VERSION ""

NS_ :

BS_:

BU_: XXX

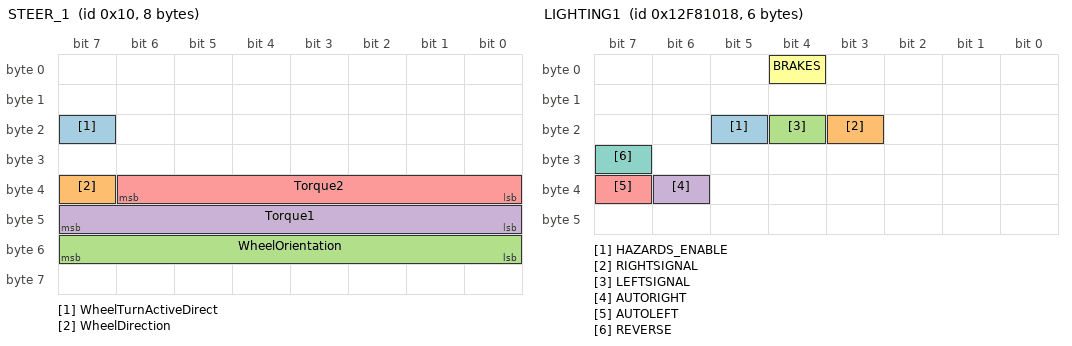
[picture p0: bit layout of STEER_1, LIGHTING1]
BO_ 16 STEER_1: 8 XXX
 SG_ WheelTurnActiveDirect : 23|1@0+ (1,0) [0|255] "" XXX
 SG_ WheelDirection : 39|1@0+ (1,0) [0|1] "" XXX
 SG_ WheelOrientation : 55|8@0+ (1,0) [0|255] "" XXX
 SG_ Torque1 : 40|8@1+ (1,0) [0|255] "" XXX
 SG_ Torque2 : 38|7@0+ (1,0) [0|127] "" XXX

BO_ 516 GAS: 8 XXX
 SG_ UserGasPosition : 1|18@0+ (1,0) [0|65535] "" XXX

BO_ 125 BRAKE1: 8 XXX
 SG_ PedalPosition : 7|16@0+ (1,0) [0|65535] "" XXX

BO_ 318246936 LIGHTING1: 6 XXX
 SG_ HAZARDS_ENABLE : 21|1@0+ (1,0) [0|1] "" XXX
 SG_ RIGHTSIGNAL : 19|1@0+ (1,0) [0|1] "" XXX
 SG_ LEFTSIGNAL : 20|1@0+ (1,0) [0|3] "" XXX
 SG_ AUTORIGHT : 38|1@0+ (1,0) [0|1] "" XXX
 SG_ AUTOLEFT : 39|1@0+ (1,0) [0|1] "" XXX
 SG_ BRAKES : 4|1@0+ (1,0) [0|1] "" XXX
 SG_ REVERSE : 31|1@0+ (1,0) [0|1] "" XXX

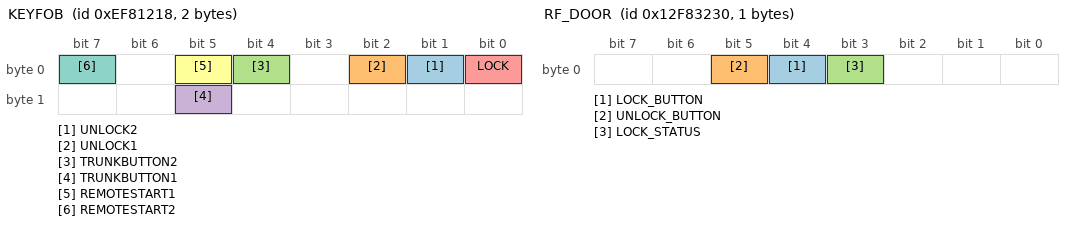
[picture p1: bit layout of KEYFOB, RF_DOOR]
BO_ 251138584 KEYFOB: 2 XXX
 SG_ UNLOCK2 : 1|1@0+ (1,0) [0|1] "" XXX
 SG_ UNLOCK1 : 2|1@0+ (1,0) [0|1] "" XXX
 SG_ TRUNKBUTTON2 : 4|1@0+ (1,0) [0|1] "" XXX
 SG_ TRUNKBUTTON1 : 13|1@0+ (1,0) [0|1] "" XXX
 SG_ LOCK : 0|1@0+ (1,0) [0|1] "" XXX
 SG_ REMOTESTART1 : 5|1@0+ (1,0) [0|1] "" XXX
 SG_ REMOTESTART2 : 7|1@0+ (1,0) [0|1] "" XXX

BO_ 318255664 RF_DOOR: 1 XXX
 SG_ LOCK_BUTTON : 4|1@0+ (1,0) [0|1] "" XXX
 SG_ UNLOCK_BUTTON : 5|1@0+ (1,0) [0|1] "" XXX
 SG_ LOCK_STATUS : 3|1@0+ (1,0) [0|1] "" XXX

BO_ 318255408 DOOR_STATUS2: 8 XXX

BO_ 184057368 LIGHTING2: 3 XXX

BO_ 318264400 LIGHTING3: 8 XXX
 SG_ PARKING_LIGHTS : 6|1@0+ (1,0) [0|1] "" XXX

BO_ 184029464 LIGHTING4: 6 XXX

BO_ 184053784 LIGHTING_STALK1: 3 XXX

BO_ 318259736 RR_DOOR: 1 XXX
 SG_ LOCK_STATUS : 7|1@0+ (1,0) [0|1] "" XXX

BO_ 318288034 HEATED_SEATS: 2 XXX
 SG_ PASS_SEAT : 2|2@0+ (1,0) [0|3] "" XXX
 SG_ DRIVER_SEAT : 6|2@0+ (1,0) [0|3] "" XXX

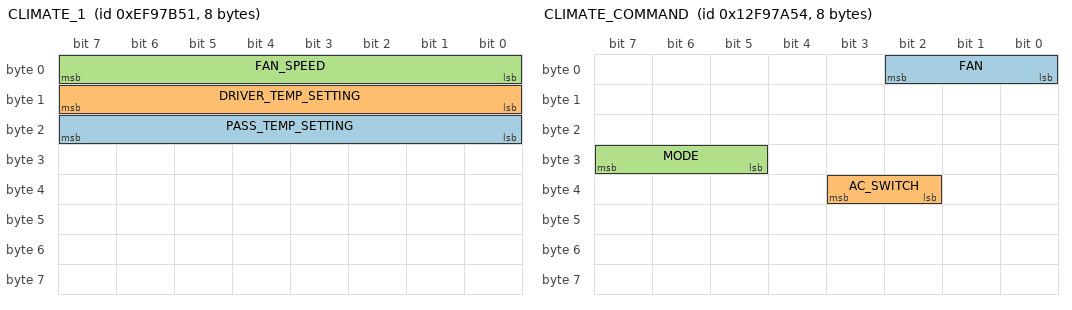
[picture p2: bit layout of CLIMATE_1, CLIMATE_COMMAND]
BO_ 251231057 CLIMATE_1: 8 XXX
 SG_ PASS_TEMP_SETTING : 16|8@1+ (1,0) [0|255] "" XXX
 SG_ DRIVER_TEMP_SETTING : 8|8@1+ (1,0) [0|255] "" XXX
 SG_ FAN_SPEED : 0|8@1+ (1,0) [0|255] "" XXX

BO_ 251142168 DOOR_LOCKS: 1 XXX
 SG_ LOCKACTION_STATUS : 7|2@0+ (1,0) [0|1] "" XXX

BO_ 318339668 CLIMATE_COMMAND: 8 XXX
 SG_ FAN : 0|3@1+ (1,0) [0|7] "" XXX
 SG_ AC_SWITCH : 34|2@1+ (1,0) [0|3] "" XXX
 SG_ MODE : 31|3@0+ (1,0) [0|7] "" XXX

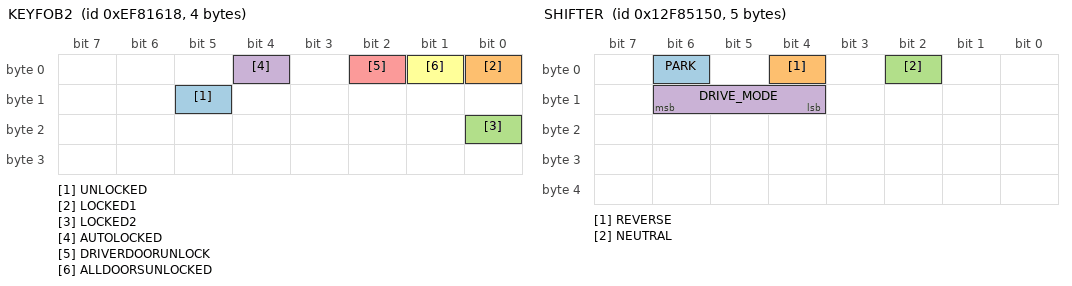
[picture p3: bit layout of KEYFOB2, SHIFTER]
BO_ 251139608 KEYFOB2: 4 XXX
 SG_ UNLOCKED : 13|1@0+ (1,0) [0|1] "" XXX
 SG_ LOCKED1 : 0|1@0+ (1,0) [0|1] "" XXX
 SG_ LOCKED2 : 16|1@0+ (1,0) [0|1] "" XXX
 SG_ AUTOLOCKED : 4|1@0+ (1,0) [0|1] "" XXX
 SG_ DRIVERDOORUNLOCK : 2|1@0+ (1,0) [0|1] "" XXX
 SG_ ALLDOORSUNLOCKED : 1|1@0+ (1,0) [0|1] "" XXX

BO_ 318260272 FRONT_WINDOWS: 2 XXX
 SG_ RF_WINDOWSTATE : 14|1@0+ (1,0) [0|1] "" XXX
 SG_ LF_WINDOWSTATE : 15|1@0+ (1,0) [0|1] "" XXX

BO_ 318263376 CONSOLE_SWITCHES: 6 XXX
 SG_ ECO_SWITCH : 29|1@0+ (1,0) [0|1] "" XXX
 SG_ ENGINE_RPM : 15|16@0+ (1,0) [0|65535] "" XXX

BO_ 318263632 SHIFTER: 5 XXX
 SG_ PARK : 6|1@0+ (1,0) [0|1] "" XXX
 SG_ REVERSE : 4|1@0+ (1,0) [0|1] "" XXX
 SG_ NEUTRAL : 2|1@0+ (1,0) [0|1] "" XXX
 SG_ DRIVE_MODE : 14|3@0+ (1,0) [0|7] "" XXX

BO_ 318337360 STEERING: 3 XXX

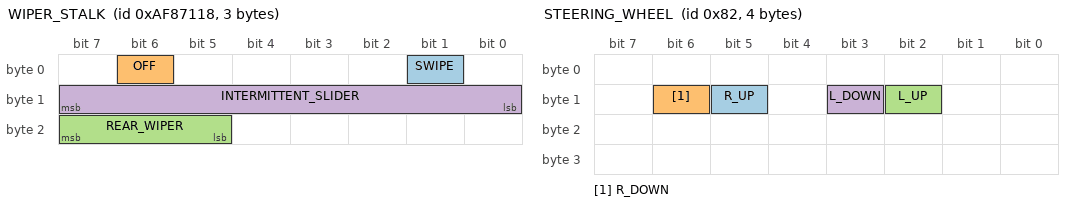
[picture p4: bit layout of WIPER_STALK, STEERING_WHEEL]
BO_ 184054040 WIPER_STALK: 3 XXX
 SG_ SWIPE : 1|1@0+ (1,0) [0|1] "" XXX
 SG_ OFF : 6|1@0+ (1,0) [0|1] "" XXX
 SG_ REAR_WIPER : 23|3@0+ (1,0) [0|7] "" XXX
 SG_ INTERMITTENT_SLIDER : 15|8@0+ (1,0) [0|255] "" XXX

BO_ 130 STEERING_WHEEL: 4 XXX
 SG_ R_UP : 13|1@0+ (1,0) [0|1] "" XXX
 SG_ R_DOWN : 14|1@0+ (1,0) [0|1] "" XXX
 SG_ L_UP : 10|1@0+ (1,0) [0|1] "" XXX
 SG_ L_DOWN : 11|1@0+ (1,0) [0|1] "" XXX

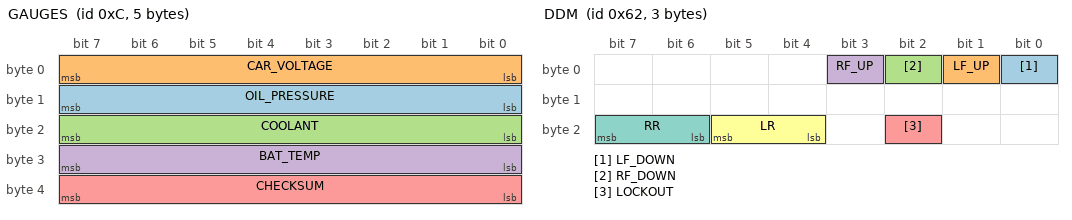
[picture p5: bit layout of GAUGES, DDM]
BO_ 12 GAUGES: 5 XXX
 SG_ OIL_PRESSURE : 15|8@0+ (0.5,0) [0|255] "psi" XXX
 SG_ CAR_VOLTAGE : 7|8@0+ (0.125,0) [0|255] "volts" XXX
 SG_ COOLANT : 23|8@0+ (1,-64) [0|255] "c" XXX
 SG_ BAT_TEMP : 24|8@1+ (1,-64) [0|255] "" XXX
 SG_ CHECKSUM : 39|8@0+ (1,0) [0|255] "" XXX

BO_ 98 DDM: 3 XXX
 SG_ LF_DOWN : 0|1@0+ (1,0) [0|1] "" XXX
 SG_ LF_UP : 1|1@1+ (1,0) [0|1] "" XXX
 SG_ RF_DOWN : 2|1@0+ (1,0) [0|1] "" XXX
 SG_ RF_UP : 3|1@0+ (1,0) [0|1] "" XXX
 SG_ LOCKOUT : 18|1@0+ (1,0) [0|1] "" XXX
 SG_ LR : 21|2@0+ (1,0) [0|1] "" XXX
 SG_ RR : 23|2@0+ (1,0) [0|3] "1 = IDLE, 0 = DOWN, 3 = UP" XXX

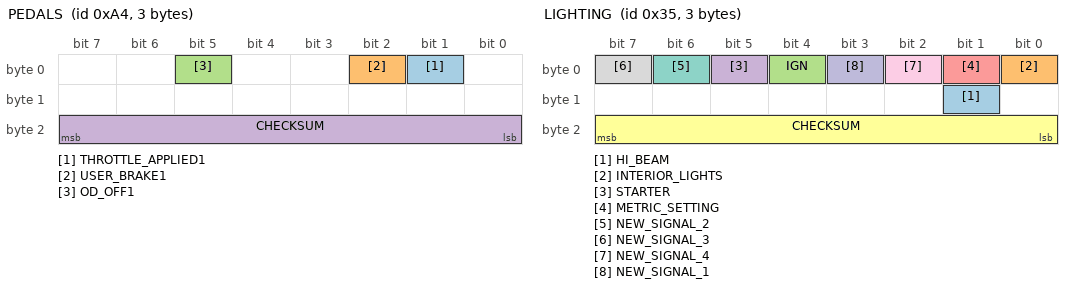
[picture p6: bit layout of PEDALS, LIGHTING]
BO_ 164 PEDALS: 3 XXX
 SG_ THROTTLE_APPLIED1 : 1|1@0+ (1,0) [0|1] "" XXX
 SG_ USER_BRAKE1 : 2|1@0+ (1,0) [0|1] "" XXX
 SG_ OD_OFF1 : 5|1@0+ (1,0) [0|1] "" XXX
 SG_ CHECKSUM : 23|8@0+ (1,0) [0|255] "" XXX

BO_ 53 LIGHTING: 3 XXX
 SG_ HI_BEAM : 9|1@0+ (1,0) [0|1] "" XXX
 SG_ INTERIOR_LIGHTS : 0|1@0+ (1,0) [0|1] "" XXX
 SG_ IGN : 4|1@1+ (1,0) [0|127] "" XXX
 SG_ STARTER : 5|1@0+ (1,0) [0|1] "" XXX
 SG_ METRIC_SETTING : 1|1@0+ (1,0) [0|1] "" XXX
 SG_ CHECKSUM : 23|8@0+ (1,0) [0|255] "" XXX
 SG_ NEW_SIGNAL_2 : 6|1@0+ (1,0) [0|1] "" XXX
 SG_ NEW_SIGNAL_3 : 7|1@0+ (1,0) [0|1] "" XXX
 SG_ NEW_SIGNAL_4 : 2|1@0+ (1,0) [0|1] "" XXX
 SG_ NEW_SIGNAL_1 : 3|1@0+ (1,0) [0|1] "" XXX

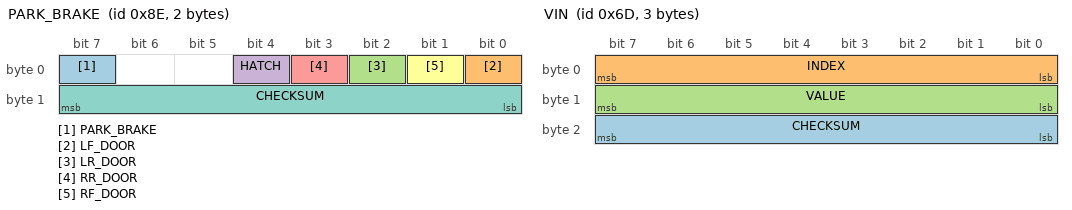
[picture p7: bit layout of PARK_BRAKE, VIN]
BO_ 142 PARK_BRAKE: 2 XXX
 SG_ PARK_BRAKE : 7|1@0+ (1,0) [0|1] "" XXX
 SG_ LF_DOOR : 0|1@0+ (1,0) [0|1] "" XXX
 SG_ LR_DOOR : 2|1@0+ (1,0) [0|1] "" XXX
 SG_ HATCH : 4|1@0+ (1,0) [0|1] "" XXX
 SG_ RR_DOOR : 3|1@0+ (1,0) [0|1] "" XXX
 SG_ RF_DOOR : 1|1@0+ (1,0) [0|1] "" XXX
 SG_ CHECKSUM : 15|8@0+ (1,0) [0|255] "" XXX

BO_ 109 VIN: 3 XXX
 SG_ CHECKSUM : 23|8@0+ (1,0) [0|255] "" XXX
 SG_ INDEX : 7|8@0+ (1,0) [0|255] "" XXX
 SG_ VALUE : 15|8@0+ (1,0) [0|255] "" XXX

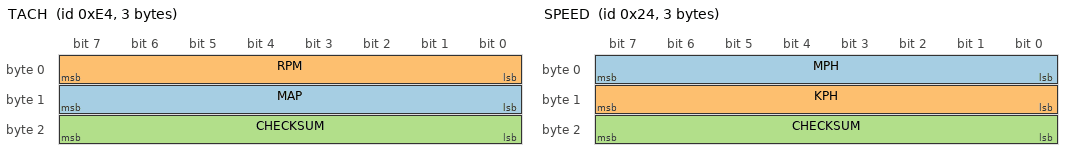
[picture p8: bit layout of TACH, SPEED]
BO_ 228 TACH: 3 XXX
 SG_ MAP : 15|8@0+ (1,0) [0|255] "" XXX
 SG_ RPM : 7|8@0+ (32,0) [0|16777215] "" XXX
 SG_ CHECKSUM : 23|8@0+ (1,0) [0|255] "" XXX

BO_ 36 SPEED: 3 XXX
 SG_ MPH : 7|8@0+ (1,0) [0|255] "" XXX
 SG_ KPH : 15|8@0+ (1,0) [0|255] "" XXX
 SG_ CHECKSUM : 23|8@0+ (1,0) [0|255] "" XXX

BO_ 206 ODOMETER: 5 XXX
 SG_ ODO1 : 0|32@1+ (0.000124355,0) [0|1] "" XXX

BO_ 37 FUEL: 2 XXX
 SG_ FUEL_LEVEL : 7|8@0+ (0.395,0) [0|255] "" XXX
 SG_ CHECKSUM : 15|8@0+ (1,0) [0|255] "" XXX

BO_ 254 DIMMER: 2 XXX
 SG_ DIMMER_SLIDER : 0|8@1+ (1,0) [0|255] "" XXX

BO_ 126 HVAC: 2 XXX
 SG_ AC_REQUEST : 0|1@0+ (1,0) [0|1] "" XXX

BO_ 123 EXT_TEMP: 2 XXX
 SG_ EXT_TEMP : 7|8@0+ (0.15,0) [0|255] "" XXX

BO_ 132 SPEED_2: 3 XXX
 SG_ SPEED : 15|8@0+ (1,0) [0|255] "" XXX
 SG_ CHECKSUM : 23|8@0+ (1,0) [0|255] "" XXX

BO_ 68 NEW_MSG_1: 8 XXX
 SG_ NEW_SIGNAL_1 : 7|8@0+ (1,0) [0|255] "" XXX

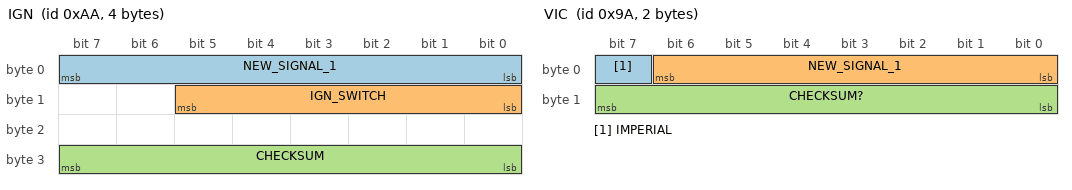
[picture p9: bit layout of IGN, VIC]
BO_ 170 IGN: 4 XXX
 SG_ NEW_SIGNAL_1 : 7|8@0+ (1,0) [0|255] "" XXX
 SG_ IGN_SWITCH : 13|6@0+ (1,0) [0|255] "" XXX
 SG_ CHECKSUM : 31|8@0+ (1,0) [0|255] "" XXX

BO_ 154 VIC: 2 XXX
 SG_ IMPERIAL : 7|1@0+ (1,0) [0|1] "" XXX
 SG_ NEW_SIGNAL_1 : 6|7@0+ (1,0) [0|127] "" XXX
 SG_ CHECKSUM? : 15|8@0+ (1,0) [0|255] "" XXX

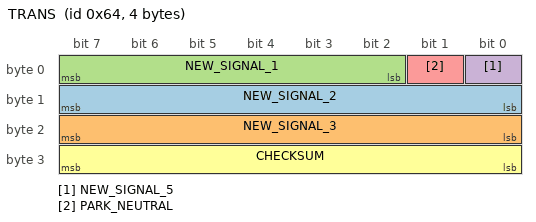
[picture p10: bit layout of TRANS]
BO_ 100 TRANS: 4 XXX
 SG_ NEW_SIGNAL_2 : 15|8@0+ (1,0) [0|255] "" XXX
 SG_ NEW_SIGNAL_3 : 23|8@0+ (1,0) [0|255] "" XXX
 SG_ NEW_SIGNAL_1 : 2|6@1+ (1,0) [0|255] "" XXX
 SG_ NEW_SIGNAL_5 : 0|1@0+ (1,0) [0|1] "" XXX
 SG_ PARK_NEUTRAL : 1|1@0+ (1,0) [0|1] "" XXX
 SG_ CHECKSUM : 31|8@0+ (1,0) [0|255] "" XXX

BO_ 238 NEW_MSG_2: 8 XXX
 SG_ NEW_SIGNAL_3 : 7|8@0+ (1,0) [0|255] "" XXX
 SG_ MAYBE_TRIP1 : 15|16@0+ (1,0) [0|255] "" XXX

BO_ 204 NEW_MSG_3: 8 XXX

BO_ 35 NEW_MSG_4: 8 XXX
 SG_ NEW_SIGNAL_1 : 7|8@0+ (1,0) [0|255] "" XXX
 SG_ NEW_SIGNAL_2 : 15|8@0+ (1,0) [0|255] "" XXX

CM_ SG_ 16 WheelTurnActiveDirect "0-wheel going ccw,1-wheel going cw";
CM_ SG_ 16 WheelDirection "0-left,1-right. ";
CM_ SG_ 318255664 LOCK_STATUS "LOCKED = 0, UNLOCKED = 1";
CM_ SG_ 318264400 PARKING_LIGHTS "0 = OFF, 1 = ON";
CM_ SG_ 318259736 LOCK_STATUS "LOCKED = 0, UNLOCKED = 1";
CM_ SG_ 318288034 PASS_SEAT "0 = OFF, 1 = HIGH, 2 = MED, 3 = LO";
CM_ SG_ 318288034 DRIVER_SEAT "0 = OFF, 1 = HIGH, 2 = MED, 3 = LO";
CM_ SG_ 251231057 PASS_TEMP_SETTING "04 = HIGH, 08 = LO";
CM_ SG_ 251231057 DRIVER_TEMP_SETTING "04 = HIGH, 08 = LO";
CM_ SG_ 251231057 FAN_SPEED "en = current n setting, 6n = going to n setting";
CM_ SG_ 251142168 LOCKACTION_STATUS "0 = IDLE, 1 = UNLOCKING, 2 = LOCKING";
CM_ SG_ 318339668 MODE "5 = FACE, 4 = MIX, 3 = FLOOR, 2 = FLOOR_DEFROST";
CM_ SG_ 251139608 AUTOLOCKED "1 = CAR AUTOLOCKED";
CM_ SG_ 318260272 RF_WINDOWSTATE "1 = CLOSED, 0 = OPEN";
CM_ SG_ 318260272 LF_WINDOWSTATE "1 = CLOSED, 0 = OPEN";
CM_ SG_ 318263632 DRIVE_MODE "0 = DRIVE, 4 = S, 1 = L";
CM_ SG_ 184054040 REAR_WIPER "0 = OFF, 4 = INT, 1 = ON";
CM_ SG_ 98 LF_DOWN "0 = active";
CM_ SG_ 98 LF_UP "0 = active";
CM_ SG_ 98 RF_DOWN "0 = active";
CM_ SG_ 98 RF_UP "0 = active";
CM_ SG_ 98 LOCKOUT "1 = active";
CM_ SG_ 98 LR "2 = IDLE, 1 = DOWN, 0 = UP";
CM_ SG_ 37 FUEL_LEVEL "0 = SHORT, 255 = OPEN, RANGE = 1-253";
CM_ SG_ 254 DIMMER_SLIDER "fd = max w lights on, ff= max lights off/lights off";
CM_ SG_ 170 IGN_SWITCH "32 OFF/UNLOCKED, 33 ?, 34 ACC, 35 RUN";
